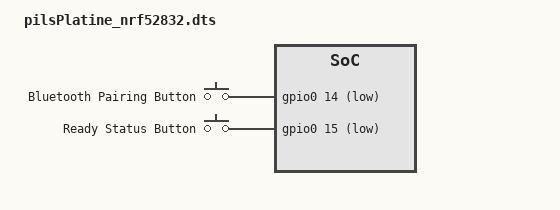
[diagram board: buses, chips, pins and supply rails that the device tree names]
/* pilsplatine_nrf52832.dts */
/dts-v1/;
#include "pilsplatine_common.dtsi"

/ {
    /* Add the extra buttons to the existing container */
    buttons {
        pairing_btn: button_pairing {
            gpios = <&gpio0 14 (GPIO_PULL_UP | GPIO_ACTIVE_LOW)>;
            label = "Bluetooth Pairing Button";
        };
        ready_btn: button_ready {
            gpios = <&gpio0 15 (GPIO_ACTIVE_LOW)>;
            label = "Ready Status Button";
        };
    };

    aliases {
        buttonpairing = &pairing_btn;
        buttonrdy = &ready_btn;
    };
};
